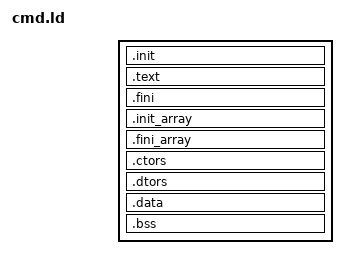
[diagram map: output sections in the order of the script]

ENTRY(_start)

SECTIONS
{
    PROVIDE (__executable_start = SEGMENT_START("text-segment", 0x400000)); . = SEGMENT_START("text-segment", 0x400000) + SIZEOF_HEADERS;  

    .init :
    {
        KEEP (*(SORT_NONE(.init)))
    }

    .text :
    {
        *(.text*)
    }

    .fini :
    {
        KEEP (*(SORT_NONE(.fini)))
    }

    PROVIDE (__etext = .);
    PROVIDE (_etext = .);
    PROVIDE (etext = .);

    .init_array :
    {
        PROVIDE_HIDDEN (__init_array_start = .);
        KEEP (*(SORT_BY_INIT_PRIORITY(.init_array.*) SORT_BY_INIT_PRIORITY(.ctors.*)))
        KEEP (*(.init_array EXCLUDE_FILE (*crtbegin.o *crtbegin?.o *crtend.o *crtend?.o ) .ctors))
        PROVIDE_HIDDEN (__init_array_end = .);
    }
    .fini_array :
    {
        PROVIDE_HIDDEN (__fini_array_start = .);
        KEEP (*(SORT_BY_INIT_PRIORITY(.fini_array.*) SORT_BY_INIT_PRIORITY(.dtors.*)))
        KEEP (*(.fini_array EXCLUDE_FILE (*crtbegin.o *crtbegin?.o *crtend.o *crtend?.o ) .dtors))
        PROVIDE_HIDDEN (__fini_array_end = .);
    }

    .ctors :
    {
        /* gcc uses crtbegin.o to find the start of
        the constructors, so we make sure it is
        first.  Because this is a wildcard, it
        doesn't matter if the user does not
        actually link against crtbegin.o; the
        linker won't look for a file to match a
        wildcard.  The wildcard also means that it
        doesn't matter which directory crtbegin.o
        is in.  */

        KEEP (*crtbegin.o(.ctors))
        KEEP (*crtbegin?.o(.ctors))

        /* We don't want to include the .ctor section from
        the crtend.o file until after the sorted ctors.
        The .ctor section from the crtend file contains the
        end of ctors marker and it must be last */
        KEEP (*(EXCLUDE_FILE (*crtend.o *crtend?.o ) .ctors))
        KEEP (*(SORT(.ctors.*)))
        KEEP (*(.ctors))
    }

    .dtors :
    {
        KEEP (*crtbegin.o(.dtors))
        KEEP (*crtbegin?.o(.dtors))
        KEEP (*(EXCLUDE_FILE (*crtend.o *crtend?.o ) .dtors))
        KEEP (*(SORT(.dtors.*)))
        KEEP (*(.dtors))
    }

    .data   :
    {
        *(.data .data.*)
        SORT(CONSTRUCTORS)
    }

    _edata = .; PROVIDE (edata = .);
    . = .;
    __bss_start = .;
    .bss            :
    {
        *(.dynbss)
        *(.bss .bss.* )
        *(COMMON)
        /* Align here to ensure that the .bss section occupies space up to
        _end.  Align after .bss to ensure correct alignment even if the
        .bss section disappears because there are no input sections.
        FIXME: Why do we need it? When there is no .bss section, we don't
        pad the .data section.  */
        . = ALIGN(. != 0 ? 64 / 8 : 1);
    }
    . = ALIGN(64 / 8);




    . = ALIGN(64 / 8);
    _end = .; PROVIDE (end = .);


    /DISCARD/ : { *(.note.GNU-stack) *(.gnu_debuglink) *(.gnu.lto_*) }
}
